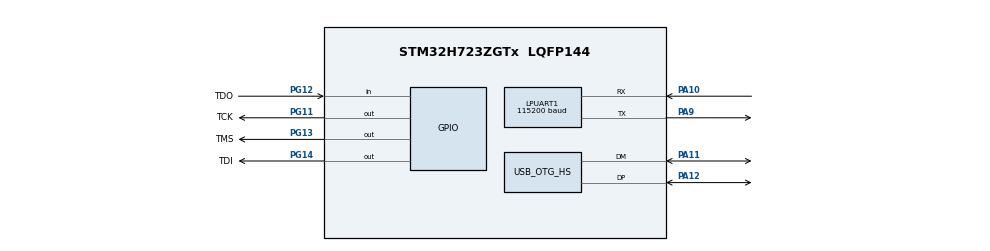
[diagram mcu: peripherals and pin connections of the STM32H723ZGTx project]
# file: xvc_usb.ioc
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LPUART1.BaudRate=115200
Mcu.Family=STM32H7
Mcu.Name=STM32H723ZGTx
Mcu.Package=LQFP144
NVIC.OTG_HS_IRQn=true\:0\:0\:false\:false\:true\:false\:true\:true
NVIC.PriorityGroup=NVIC_PRIORITYGROUP_4
PA10.Mode=Asynchronous
PA10.Signal=LPUART1_RX
PA11.Mode=Device_Only_FS
PA11.Signal=USB_OTG_HS_DM
PA12.Mode=Device_Only_FS
PA12.Signal=USB_OTG_HS_DP
PA13(JTMS/SWDIO).Mode=Serial_Wire
PA13(JTMS/SWDIO).Signal=DEBUG_JTMS-SWDIO
PA14(JTCK/SWCLK).Mode=Serial_Wire
PA14(JTCK/SWCLK).Signal=DEBUG_JTCK-SWCLK
PA9.Mode=Asynchronous
PA9.Signal=LPUART1_TX
PG11.GPIO_Label=TCK
PG11.GPIO_Speed=GPIO_SPEED_FREQ_VERY_HIGH
PG11.Signal=GPIO_Output
PG12.GPIO_Label=TDO
PG12.Signal=GPIO_Input
PG13.GPIO_Label=TMS
PG13.GPIO_Speed=GPIO_SPEED_FREQ_VERY_HIGH
PG13.PinState=GPIO_PIN_SET
PG13.Signal=GPIO_Output
PG14.GPIO_Label=TDI
PG14.GPIO_Speed=GPIO_SPEED_FREQ_VERY_HIGH
PG14.Signal=GPIO_Output
PH0-OSC_IN.Mode=HSE-External-Oscillator
PH0-OSC_IN.Signal=RCC_OSC_IN
PH1-OSC_OUT.Mode=HSE-External-Oscillator
PH1-OSC_OUT.Signal=RCC_OSC_OUT
ProjectManager.HeapSize=0x200
ProjectManager.StackSize=0x400
ProjectManager.TargetToolchain=STM32CubeIDE
RCC.ADCFreq_Value=50390625
RCC.APB1Freq_Value=137500000
RCC.APB2Freq_Value=137500000
RCC.APB3Freq_Value=137500000
RCC.APB4Freq_Value=137500000
RCC.CortexFreq_Value=550000000
RCC.D1PPRE=RCC_APB3_DIV2
RCC.D2PPRE1=RCC_APB1_DIV2
RCC.D2PPRE2=RCC_APB2_DIV2
RCC.D3PPRE=RCC_APB4_DIV2
RCC.DIVM1=2
RCC.DIVN1=44
RCC.DIVP1=1
RCC.DIVQ1=5
RCC.HCLKFreq_Value=275000000
RCC.HPRE=RCC_HCLK_DIV2
RCC.PLLFRACN=0
RCC.PLLSourceVirtual=RCC_PLLSOURCE_HSE
RCC.SYSCLKFreq_VALUE=550000000
RCC.SYSCLKSource=RCC_SYSCLKSOURCE_PLLCLK
RCC.USBCLockSelection=RCC_USBCLKSOURCE_HSI48
RCC.USBFreq_Value=48000000
USB_DEVICE.CLASS_NAME_HS=CDC
USB_DEVICE.VirtualMode=Cdc
USB_DEVICE.VirtualModeHS=Cdc_HS
USB_OTG_HS.VirtualMode-Device_Only_FS=Device_Only_FS
VP_MEMORYMAP_VS_MEMORYMAP.Mode=CurAppReg
VP_USB_DEVICE_VS_USB_DEVICE_CDC_HS.Mode=CDC_HS
board=custom

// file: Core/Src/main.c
/* USER CODE BEGIN Header */
/**
  ******************************************************************************
  * @file           : main.c
  * @brief          : Main program body
  ******************************************************************************
  * @attention
  *
  * Copyright (c) 2025 STMicroelectronics.
  * All rights reserved.
  *
  * This software is licensed under terms that can be found in the LICENSE file
  * in the root directory of this software component.
  * If no LICENSE file comes with this software, it is provided AS-IS.
  *
  ******************************************************************************
  */
/* USER CODE END Header */
#include "main.h"
#include "usb_device.h"

UART_HandleTypeDef hlpuart1;

void SystemClock_Config(void);
static void MX_GPIO_Init(void);
static void MX_LPUART1_UART_Init(void);

int main(void)
{

  /* MCU Configuration--------------------------------------------------------*/

  /* Reset of all peripherals, Initializes the Flash interface and the Systick. */
  HAL_Init();

  /* Configure the system clock */
  SystemClock_Config();

  /* Initialize all configured peripherals */
  MX_GPIO_Init();
  MX_LPUART1_UART_Init();
  MX_USB_DEVICE_Init();

  /* Infinite loop */
  /* USER CODE BEGIN WHILE */
  while (1)
  {
	  HAL_Delay(10);
    /* USER CODE END WHILE */

  }
}

void SystemClock_Config(void)
{
  RCC_OscInitTypeDef RCC_OscInitStruct = {0};
  RCC_ClkInitTypeDef RCC_ClkInitStruct = {0};

  /** Supply configuration update enable
  */
  HAL_PWREx_ConfigSupply(PWR_LDO_SUPPLY);

  /** Configure the main internal regulator output voltage
  */
  __HAL_PWR_VOLTAGESCALING_CONFIG(PWR_REGULATOR_VOLTAGE_SCALE0);

  while(!__HAL_PWR_GET_FLAG(PWR_FLAG_VOSRDY)) {}

  /** Initializes the RCC Oscillators according to the specified parameters
  * in the RCC_OscInitTypeDef structure.
  */
  RCC_OscInitStruct.OscillatorType = RCC_OSCILLATORTYPE_HSI48|RCC_OSCILLATORTYPE_HSE;
  RCC_OscInitStruct.HSEState = RCC_HSE_ON;
  RCC_OscInitStruct.HSI48State = RCC_HSI48_ON;
  RCC_OscInitStruct.PLL.PLLState = RCC_PLL_ON;
  RCC_OscInitStruct.PLL.PLLSource = RCC_PLLSOURCE_HSE;
  RCC_OscInitStruct.PLL.PLLM = 2;
  RCC_OscInitStruct.PLL.PLLN = 44;
  RCC_OscInitStruct.PLL.PLLP = 1;
  RCC_OscInitStruct.PLL.PLLQ = 5;
  RCC_OscInitStruct.PLL.PLLR = 2;
  RCC_OscInitStruct.PLL.PLLRGE = RCC_PLL1VCIRANGE_3;
  RCC_OscInitStruct.PLL.PLLVCOSEL = RCC_PLL1VCOWIDE;
  RCC_OscInitStruct.PLL.PLLFRACN = 0;
  if (HAL_RCC_OscConfig(&RCC_OscInitStruct) != HAL_OK)
  {
    Error_Handler();
  }

  /** Initializes the CPU, AHB and APB buses clocks
  */
  RCC_ClkInitStruct.ClockType = RCC_CLOCKTYPE_HCLK|RCC_CLOCKTYPE_SYSCLK
                              |RCC_CLOCKTYPE_PCLK1|RCC_CLOCKTYPE_PCLK2
                              |RCC_CLOCKTYPE_D3PCLK1|RCC_CLOCKTYPE_D1PCLK1;
  RCC_ClkInitStruct.SYSCLKSource = RCC_SYSCLKSOURCE_PLLCLK;
  RCC_ClkInitStruct.SYSCLKDivider = RCC_SYSCLK_DIV1;
  RCC_ClkInitStruct.AHBCLKDivider = RCC_HCLK_DIV2;
  RCC_ClkInitStruct.APB3CLKDivider = RCC_APB3_DIV2;
  RCC_ClkInitStruct.APB1CLKDivider = RCC_APB1_DIV2;
  RCC_ClkInitStruct.APB2CLKDivider = RCC_APB2_DIV2;
  RCC_ClkInitStruct.APB4CLKDivider = RCC_APB4_DIV2;

  if (HAL_RCC_ClockConfig(&RCC_ClkInitStruct, FLASH_LATENCY_3) != HAL_OK)
  {
    Error_Handler();
  }
}

static void MX_LPUART1_UART_Init(void)
{

  hlpuart1.Instance = LPUART1;
  hlpuart1.Init.BaudRate = 115200;
  hlpuart1.Init.WordLength = UART_WORDLENGTH_8B;
  hlpuart1.Init.StopBits = UART_STOPBITS_1;
  hlpuart1.Init.Parity = UART_PARITY_NONE;
  hlpuart1.Init.Mode = UART_MODE_TX_RX;
  hlpuart1.Init.HwFlowCtl = UART_HWCONTROL_NONE;
  hlpuart1.Init.OneBitSampling = UART_ONE_BIT_SAMPLE_DISABLE;
  hlpuart1.Init.ClockPrescaler = UART_PRESCALER_DIV1;
  hlpuart1.AdvancedInit.AdvFeatureInit = UART_ADVFEATURE_NO_INIT;
  hlpuart1.FifoMode = UART_FIFOMODE_DISABLE;
  if (HAL_UART_Init(&hlpuart1) != HAL_OK)
  {
    Error_Handler();
  }
  if (HAL_UARTEx_SetTxFifoThreshold(&hlpuart1, UART_TXFIFO_THRESHOLD_1_8) != HAL_OK)
  {
    Error_Handler();
  }
  if (HAL_UARTEx_SetRxFifoThreshold(&hlpuart1, UART_RXFIFO_THRESHOLD_1_8) != HAL_OK)
  {
    Error_Handler();
  }
  if (HAL_UARTEx_DisableFifoMode(&hlpuart1) != HAL_OK)
  {
    Error_Handler();
  }

}

static void MX_GPIO_Init(void)
{
  GPIO_InitTypeDef GPIO_InitStruct = {0};

  /* GPIO Ports Clock Enable */
  __HAL_RCC_GPIOH_CLK_ENABLE();
  __HAL_RCC_GPIOA_CLK_ENABLE();
  __HAL_RCC_GPIOG_CLK_ENABLE();

  /*Configure GPIO pin Output Level */
  HAL_GPIO_WritePin(GPIOG, TCK_Pin|TDI_Pin, GPIO_PIN_RESET);

  /*Configure GPIO pin Output Level */
  HAL_GPIO_WritePin(TMS_GPIO_Port, TMS_Pin, GPIO_PIN_SET);

  /*Configure GPIO pins : TCK_Pin TMS_Pin TDI_Pin */
  GPIO_InitStruct.Pin = TCK_Pin|TMS_Pin|TDI_Pin;
  GPIO_InitStruct.Mode = GPIO_MODE_OUTPUT_PP;
  GPIO_InitStruct.Pull = GPIO_NOPULL;
  GPIO_InitStruct.Speed = GPIO_SPEED_FREQ_VERY_HIGH;
  HAL_GPIO_Init(GPIOG, &GPIO_InitStruct);

  /*Configure GPIO pin : TDO_Pin */
  GPIO_InitStruct.Pin = TDO_Pin;
  GPIO_InitStruct.Mode = GPIO_MODE_INPUT;
  GPIO_InitStruct.Pull = GPIO_NOPULL;
  HAL_GPIO_Init(TDO_GPIO_Port, &GPIO_InitStruct);

}

void Error_Handler(void)
{
  __disable_irq();
  while (1)
  {
  }
}
